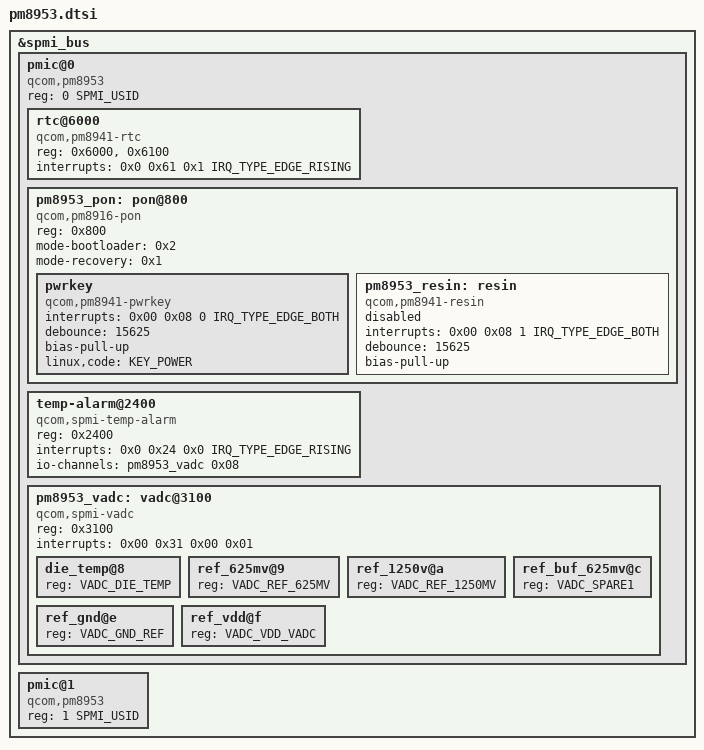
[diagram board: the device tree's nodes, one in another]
// SPDX-License-Identifier: BSD-3-Clause
/* Copyright (c) 2022, The Linux Foundation. All rights reserved. */

#include <dt-bindings/iio/qcom,spmi-vadc.h>
#include <dt-bindings/interrupt-controller/irq.h>
#include <dt-bindings/input/linux-event-codes.h>
#include <dt-bindings/spmi/spmi.h>

&spmi_bus {
	pmic@0 {
		compatible = "qcom,pm8953", "qcom,spmi-pmic";
		reg = <0 SPMI_USID>;
		#address-cells = <1>;
		#size-cells = <0>;

		rtc@6000 {
			compatible = "qcom,pm8941-rtc";
			reg = <0x6000>, <0x6100>;
			reg-names = "rtc", "alarm";
			interrupts = <0x0 0x61 0x1 IRQ_TYPE_EDGE_RISING>;
		};

		pm8953_pon: pon@800 {
			compatible = "qcom,pm8916-pon";
			reg = <0x800>;
			mode-bootloader = <0x2>;
			mode-recovery = <0x1>;

			pwrkey {
				compatible = "qcom,pm8941-pwrkey";
				interrupts = <0x00 0x08 0 IRQ_TYPE_EDGE_BOTH>;
				debounce = <15625>;
				bias-pull-up;
				linux,code = <KEY_POWER>;
			};

			pm8953_resin: resin {
				compatible = "qcom,pm8941-resin";
				interrupts = <0x00 0x08 1 IRQ_TYPE_EDGE_BOTH>;
				debounce = <15625>;
				bias-pull-up;
				status = "disabled";
			};
		};

		temp-alarm@2400 {
			compatible = "qcom,spmi-temp-alarm";
			reg = <0x2400>;
			interrupts = <0x0 0x24 0x0 IRQ_TYPE_EDGE_RISING>;
			io-channels = <&pm8953_vadc 0x08>;
			io-channel-names = "thermal";
			#thermal-sensor-cells = <0x00>;
		};

		pm8953_vadc: vadc@3100 {
			compatible = "qcom,spmi-vadc";
			reg = <0x3100>;
			interrupts = <0x00 0x31 0x00 0x01>;
			#address-cells = <1>;
			#size-cells = <0>;
			#io-channel-cells = <1>;

			die_temp@8 {
				reg = <VADC_DIE_TEMP>;
			};
			ref_625mv@9 {
				reg = <VADC_REF_625MV>;
			};
			ref_1250v@a {
				reg = <VADC_REF_1250MV>;
			};
			ref_buf_625mv@c {
				reg = <VADC_SPARE1>;
			};
			ref_gnd@e {
				reg = <VADC_GND_REF>;
			};
			ref_vdd@f {
				reg = <VADC_VDD_VADC>;
			};
		};
	};

	pmic@1 {
		compatible = "qcom,pm8953", "qcom,spmi-pmic";
		reg = <1 SPMI_USID>;
		#address-cells = <1>;
		#size-cells = <0>;
	};
};
